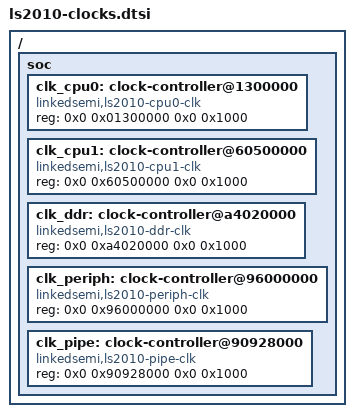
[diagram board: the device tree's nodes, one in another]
// SPDX-License-Identifier: (GPL-2.0 OR MIT)
/* Copyright (c) 2026 Linkedsemi */
/* LS2010 SoC clock providers — one node per sys_cfg register block.
 * P1 stage: read-only fixed-rate reporting (clk-ls2010.c).
 * Included by ls2010-common.dtsi; the /soc block merges with the one in
 * ls2010-common.dtsi, so the clock-controller nodes stay children of the
 * soc simple-bus and their labels remain visible to consumers in the same
 * compilation unit.
 */

/ {
	soc {
		clk_cpu0: clock-controller@1300000 {
			compatible = "linkedsemi,ls2010-cpu0-clk";
			reg = <0x0 0x01300000 0x0 0x1000>;
			#clock-cells = <1>;
			#reset-cells = <1>;
		};

		clk_cpu1: clock-controller@60500000 {
			compatible = "linkedsemi,ls2010-cpu1-clk";
			reg = <0x0 0x60500000 0x0 0x1000>;
			#clock-cells = <1>;
			#reset-cells = <1>;
		};

		clk_ddr: clock-controller@a4020000 {
			compatible = "linkedsemi,ls2010-ddr-clk";
			reg = <0x0 0xa4020000 0x0 0x1000>;
			#clock-cells = <1>;
			#reset-cells = <1>;
		};

		clk_periph: clock-controller@96000000 {
			compatible = "linkedsemi,ls2010-periph-clk";
			reg = <0x0 0x96000000 0x0 0x1000>;
			#clock-cells = <1>;
			#reset-cells = <1>;
		};

		clk_pipe: clock-controller@90928000 {
			compatible = "linkedsemi,ls2010-pipe-clk";
			reg = <0x0 0x90928000 0x0 0x1000>;
			#clock-cells = <1>;
			#reset-cells = <1>;
		};
	};
};
